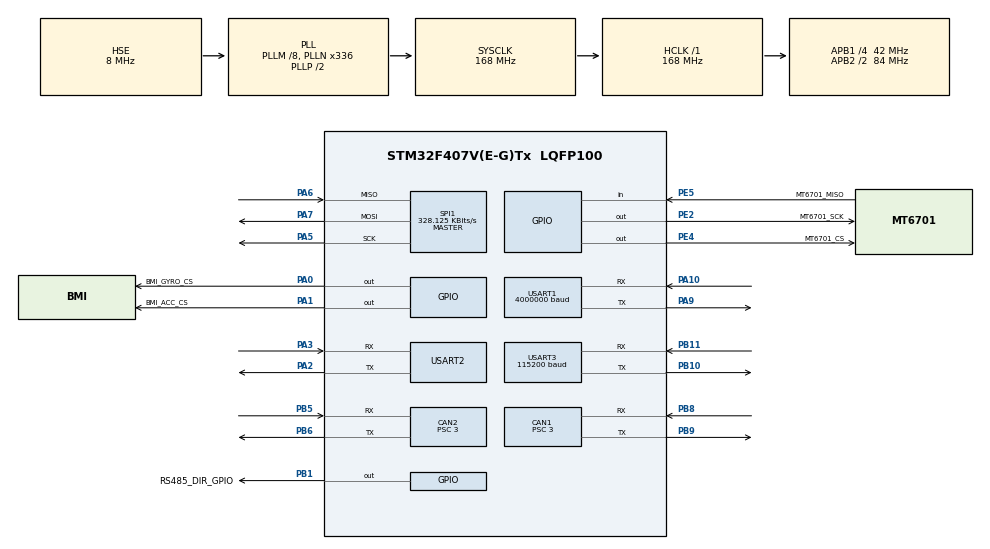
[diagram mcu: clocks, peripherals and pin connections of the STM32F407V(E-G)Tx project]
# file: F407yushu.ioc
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CAN1.ABOM=ENABLE
CAN1.AWUM=DISABLE
CAN1.BS1=CAN_BS1_8TQ
CAN1.BS2=CAN_BS2_5TQ
CAN1.CalculateBaudRate=1000000
CAN1.CalculateTimeQuantum=71.42857142857143
CAN1.Mode=CAN_MODE_NORMAL
CAN1.NART=ENABLE
CAN1.Prescaler=3
CAN1.RFLM=DISABLE
CAN1.SJW=CAN_SJW_1TQ
CAN1.TTCM=DISABLE
CAN1.TXFP=DISABLE
CAN2.ABOM=ENABLE
CAN2.AWUM=DISABLE
CAN2.BS1=CAN_BS1_8TQ
CAN2.BS2=CAN_BS2_5TQ
CAN2.CalculateBaudRate=1000000
CAN2.CalculateTimeQuantum=71.42857142857143
CAN2.Mode=CAN_MODE_NORMAL
CAN2.NART=ENABLE
CAN2.Prescaler=3
CAN2.RFLM=DISABLE
CAN2.SJW=CAN_SJW_1TQ
CAN2.TTCM=DISABLE
CAN2.TXFP=DISABLE
Mcu.Family=STM32F4
Mcu.Name=STM32F407V(E-G)Tx
Mcu.Package=LQFP100
NVIC.CAN1_RX0_IRQn=true\:0\:0\:false\:false\:true\:true\:true\:true
NVIC.CAN1_RX1_IRQn=true\:0\:0\:false\:false\:true\:true\:true\:true
NVIC.CAN1_SCE_IRQn=true\:0\:0\:false\:false\:true\:true\:true\:true
NVIC.CAN1_TX_IRQn=true\:0\:0\:false\:false\:true\:true\:true\:true
NVIC.CAN2_RX0_IRQn=true\:0\:0\:false\:false\:true\:true\:true\:true
NVIC.CAN2_RX1_IRQn=true\:0\:0\:false\:false\:true\:true\:true\:true
NVIC.CAN2_SCE_IRQn=true\:0\:0\:false\:false\:true\:true\:true\:true
NVIC.CAN2_TX_IRQn=true\:0\:0\:false\:false\:true\:true\:true\:true
NVIC.PriorityGroup=NVIC_PRIORITYGROUP_4
PA0-WKUP.GPIO_Label=BMI_GYRO_CS
PA0-WKUP.GPIO_PuPd=GPIO_NOPULL
PA0-WKUP.GPIO_Speed=GPIO_SPEED_FREQ_VERY_HIGH
PA0-WKUP.PinState=GPIO_PIN_SET
PA0-WKUP.Signal=GPIO_Output
PA1.GPIO_Label=BMI_ACC_CS
PA1.GPIO_PuPd=GPIO_NOPULL
PA1.GPIO_Speed=GPIO_SPEED_FREQ_VERY_HIGH
PA1.PinState=GPIO_PIN_SET
PA1.Signal=GPIO_Output
PA10.Mode=Asynchronous
PA10.Signal=USART1_RX
PA13.Mode=Serial_Wire
PA13.Signal=SYS_JTMS-SWDIO
PA14.Mode=Serial_Wire
PA14.Signal=SYS_JTCK-SWCLK
PA2.Mode=Asynchronous
PA2.Signal=USART2_TX
PA3.Mode=Asynchronous
PA3.Signal=USART2_RX
PA5.Mode=Full_Duplex_Master
PA5.Signal=SPI1_SCK
PA6.Mode=Full_Duplex_Master
PA6.Signal=SPI1_MISO
PA7.Mode=Full_Duplex_Master
PA7.Signal=SPI1_MOSI
PA9.Mode=Asynchronous
PA9.Signal=USART1_TX
PB1.GPIO_Label=RS485_DIR_GPIO
PB1.Signal=GPIO_Output
PB10.Mode=Asynchronous
PB10.Signal=USART3_TX
PB11.Mode=Asynchronous
PB11.Signal=USART3_RX
PB5.Mode=CAN_Activate
PB5.Signal=CAN2_RX
PB6.Mode=CAN_Activate
PB6.Signal=CAN2_TX
PB8.Mode=CAN_Activate
PB8.Signal=CAN1_RX
PB9.Mode=CAN_Activate
PB9.Signal=CAN1_TX
PE2.GPIO_Label=MT6701_SCK
PE2.GPIO_PuPd=GPIO_NOPULL
PE2.GPIO_Speed=GPIO_SPEED_FREQ_VERY_HIGH
PE2.PinState=GPIO_PIN_SET
PE2.Signal=GPIO_Output
PE4.GPIO_Label=MT6701_CS
PE4.GPIO_PuPd=GPIO_NOPULL
PE4.GPIO_Speed=GPIO_SPEED_FREQ_VERY_HIGH
PE4.PinState=GPIO_PIN_SET
PE4.Signal=GPIO_Output
PE5.GPIO_Label=MT6701_MISO
PE5.GPIO_PuPd=GPIO_NOPULL
PE5.Signal=GPIO_Input
PH0-OSC_IN.Mode=HSE-External-Oscillator
PH0-OSC_IN.Signal=RCC_OSC_IN
PH1-OSC_OUT.Mode=HSE-External-Oscillator
PH1-OSC_OUT.Signal=RCC_OSC_OUT
ProjectManager.HeapSize=0x200
ProjectManager.StackSize=0x2000
ProjectManager.TargetToolchain=MDK-ARM V5.32
RCC.48MHZClocksFreq_Value=84000000
RCC.AHBFreq_Value=168000000
RCC.APB1CLKDivider=RCC_HCLK_DIV4
RCC.APB1Freq_Value=42000000
RCC.APB1TimFreq_Value=84000000
RCC.APB2CLKDivider=RCC_HCLK_DIV2
RCC.APB2Freq_Value=84000000
RCC.APB2TimFreq_Value=168000000
RCC.CortexFreq_Value=168000000
RCC.HCLKFreq_Value=168000000
RCC.HSE_VALUE=8000000
RCC.HSI_VALUE=16000000
RCC.LSE_VALUE=32768
RCC.PLLM=8
RCC.PLLN=336
RCC.PLLSourceVirtual=RCC_PLLSOURCE_HSE
RCC.SYSCLKFreq_VALUE=168000000
RCC.SYSCLKSource=RCC_SYSCLKSOURCE_PLLCLK
RCC.VCOOutputFreq_Value=336000000
SPI1.BaudRatePrescaler=SPI_BAUDRATEPRESCALER_256
SPI1.CLKPhase=SPI_PHASE_1EDGE
SPI1.CLKPolarity=SPI_POLARITY_LOW
SPI1.CalculateBaudRate=328.125 KBits/s
SPI1.Direction=SPI_DIRECTION_2LINES
SPI1.Mode=SPI_MODE_MASTER
SPI1.VirtualType=VM_MASTER
USART1.BaudRate=4000000
USART1.OverSampling=UART_OVERSAMPLING_8
USART1.VirtualMode=VM_ASYNC
USART2.VirtualMode=VM_ASYNC
USART3.BaudRate=115200
USART3.OverSampling=UART_OVERSAMPLING_16
USART3.VirtualMode=VM_ASYNC
board=custom

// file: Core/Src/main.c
/* USER CODE BEGIN Header */
/**
  ******************************************************************************
  * @file           : main.c
  * @brief          : Main program body
  ******************************************************************************
  * @attention
  *
  * Copyright (c) 2026 STMicroelectronics.
  * All rights reserved.
  *
  * This software is licensed under terms that can be found in the LICENSE file
  * in the root directory of this software component.
  * If no LICENSE file comes with this software, it is provided AS-IS.
  *
  ******************************************************************************
  */
/* USER CODE END Header */
#include "main.h"

/* USER CODE BEGIN Includes */
#include "app.h"

/* USER CODE END Includes */

CAN_HandleTypeDef hcan1;
CAN_HandleTypeDef hcan2;

SPI_HandleTypeDef hspi1;

UART_HandleTypeDef huart1;
UART_HandleTypeDef huart2;
UART_HandleTypeDef huart3;

void SystemClock_Config(void);
static void MX_GPIO_Init(void);
static void MX_USART1_UART_Init(void);
static void MX_USART2_UART_Init(void);
static void MX_USART3_UART_Init(void);
static void MX_CAN1_Init(void);
static void MX_CAN2_Init(void);
static void MX_SPI1_Init(void);

int main(void)
{

  /* MCU Configuration--------------------------------------------------------*/

  /* Reset of all peripherals, Initializes the Flash interface and the Systick. */
  HAL_Init();

  /* Configure the system clock */
  SystemClock_Config();

  /* Initialize all configured peripherals */
  MX_GPIO_Init();
  MX_USART1_UART_Init();
  MX_USART2_UART_Init();
  MX_USART3_UART_Init();
  MX_CAN1_Init();
  MX_CAN2_Init();
  MX_SPI1_Init();
  /* USER CODE BEGIN 2 */
  App_Init();
  /* USER CODE END 2 */

  /* Infinite loop */
  while (1)
  {

    /* USER CODE BEGIN 3 */
    App_RunOnce();
  }
  /* USER CODE END 3 */
}

void SystemClock_Config(void)
{
  RCC_OscInitTypeDef RCC_OscInitStruct = {0};
  RCC_ClkInitTypeDef RCC_ClkInitStruct = {0};

  /** Configure the main internal regulator output voltage
  */
  __HAL_RCC_PWR_CLK_ENABLE();
  __HAL_PWR_VOLTAGESCALING_CONFIG(PWR_REGULATOR_VOLTAGE_SCALE1);

  /** Initializes the RCC Oscillators according to the specified parameters
  * in the RCC_OscInitTypeDef structure.
  */
  RCC_OscInitStruct.OscillatorType = RCC_OSCILLATORTYPE_HSE;
  RCC_OscInitStruct.HSEState = RCC_HSE_ON;
  RCC_OscInitStruct.PLL.PLLState = RCC_PLL_ON;
  RCC_OscInitStruct.PLL.PLLSource = RCC_PLLSOURCE_HSE;
  RCC_OscInitStruct.PLL.PLLM = 8;
  RCC_OscInitStruct.PLL.PLLN = 336;
  RCC_OscInitStruct.PLL.PLLP = RCC_PLLP_DIV2;
  RCC_OscInitStruct.PLL.PLLQ = 4;
  if (HAL_RCC_OscConfig(&RCC_OscInitStruct) != HAL_OK)
  {
    Error_Handler();
  }

  /** Initializes the CPU, AHB and APB buses clocks
  */
  RCC_ClkInitStruct.ClockType = RCC_CLOCKTYPE_HCLK|RCC_CLOCKTYPE_SYSCLK
                              |RCC_CLOCKTYPE_PCLK1|RCC_CLOCKTYPE_PCLK2;
  RCC_ClkInitStruct.SYSCLKSource = RCC_SYSCLKSOURCE_PLLCLK;
  RCC_ClkInitStruct.AHBCLKDivider = RCC_SYSCLK_DIV1;
  RCC_ClkInitStruct.APB1CLKDivider = RCC_HCLK_DIV4;
  RCC_ClkInitStruct.APB2CLKDivider = RCC_HCLK_DIV2;

  if (HAL_RCC_ClockConfig(&RCC_ClkInitStruct, FLASH_LATENCY_5) != HAL_OK)
  {
    Error_Handler();
  }
}

static void MX_CAN1_Init(void)
{

  hcan1.Instance = CAN1;
  hcan1.Init.Prescaler = 3;
  hcan1.Init.Mode = CAN_MODE_NORMAL;
  hcan1.Init.SyncJumpWidth = CAN_SJW_1TQ;
  hcan1.Init.TimeSeg1 = CAN_BS1_8TQ;
  hcan1.Init.TimeSeg2 = CAN_BS2_5TQ;
  hcan1.Init.TimeTriggeredMode = DISABLE;
  hcan1.Init.AutoBusOff = ENABLE;
  hcan1.Init.AutoWakeUp = DISABLE;
  hcan1.Init.AutoRetransmission = ENABLE;
  hcan1.Init.ReceiveFifoLocked = DISABLE;
  hcan1.Init.TransmitFifoPriority = DISABLE;
  if (HAL_CAN_Init(&hcan1) != HAL_OK)
  {
    Error_Handler();
  }

}

static void MX_CAN2_Init(void)
{

  hcan2.Instance = CAN2;
  hcan2.Init.Prescaler = 3;
  hcan2.Init.Mode = CAN_MODE_NORMAL;
  hcan2.Init.SyncJumpWidth = CAN_SJW_1TQ;
  hcan2.Init.TimeSeg1 = CAN_BS1_8TQ;
  hcan2.Init.TimeSeg2 = CAN_BS2_5TQ;
  hcan2.Init.TimeTriggeredMode = DISABLE;
  hcan2.Init.AutoBusOff = ENABLE;
  hcan2.Init.AutoWakeUp = DISABLE;
  hcan2.Init.AutoRetransmission = ENABLE;
  hcan2.Init.ReceiveFifoLocked = DISABLE;
  hcan2.Init.TransmitFifoPriority = DISABLE;
  if (HAL_CAN_Init(&hcan2) != HAL_OK)
  {
    Error_Handler();
  }

}

static void MX_SPI1_Init(void)
{

  /* SPI1 parameter configuration*/
  hspi1.Instance = SPI1;
  hspi1.Init.Mode = SPI_MODE_MASTER;
  hspi1.Init.Direction = SPI_DIRECTION_2LINES;
  hspi1.Init.DataSize = SPI_DATASIZE_8BIT;
  hspi1.Init.CLKPolarity = SPI_POLARITY_LOW;
  hspi1.Init.CLKPhase = SPI_PHASE_1EDGE;
  hspi1.Init.NSS = SPI_NSS_SOFT;
  hspi1.Init.BaudRatePrescaler = SPI_BAUDRATEPRESCALER_256;
  hspi1.Init.FirstBit = SPI_FIRSTBIT_MSB;
  hspi1.Init.TIMode = SPI_TIMODE_DISABLE;
  hspi1.Init.CRCCalculation = SPI_CRCCALCULATION_DISABLE;
  hspi1.Init.CRCPolynomial = 10;
  if (HAL_SPI_Init(&hspi1) != HAL_OK)
  {
    Error_Handler();
  }

}

static void MX_USART1_UART_Init(void)
{

  huart1.Instance = USART1;
  huart1.Init.BaudRate = 4000000;
  huart1.Init.WordLength = UART_WORDLENGTH_8B;
  huart1.Init.StopBits = UART_STOPBITS_1;
  huart1.Init.Parity = UART_PARITY_NONE;
  huart1.Init.Mode = UART_MODE_TX_RX;
  huart1.Init.HwFlowCtl = UART_HWCONTROL_NONE;
  huart1.Init.OverSampling = UART_OVERSAMPLING_8;
  if (HAL_UART_Init(&huart1) != HAL_OK)
  {
    Error_Handler();
  }

}

static void MX_USART2_UART_Init(void)
{

  huart2.Instance = USART2;
  huart2.Init.BaudRate = 115200;
  huart2.Init.WordLength = UART_WORDLENGTH_8B;
  huart2.Init.StopBits = UART_STOPBITS_1;
  huart2.Init.Parity = UART_PARITY_NONE;
  huart2.Init.Mode = UART_MODE_TX_RX;
  huart2.Init.HwFlowCtl = UART_HWCONTROL_NONE;
  huart2.Init.OverSampling = UART_OVERSAMPLING_16;
  if (HAL_UART_Init(&huart2) != HAL_OK)
  {
    Error_Handler();
  }

}

static void MX_USART3_UART_Init(void)
{

  huart3.Instance = USART3;
  huart3.Init.BaudRate = 115200;
  huart3.Init.WordLength = UART_WORDLENGTH_8B;
  huart3.Init.StopBits = UART_STOPBITS_1;
  huart3.Init.Parity = UART_PARITY_NONE;
  huart3.Init.Mode = UART_MODE_TX_RX;
  huart3.Init.HwFlowCtl = UART_HWCONTROL_NONE;
  huart3.Init.OverSampling = UART_OVERSAMPLING_16;
  if (HAL_UART_Init(&huart3) != HAL_OK)
  {
    Error_Handler();
  }

}

static void MX_GPIO_Init(void)
{
  GPIO_InitTypeDef GPIO_InitStruct = {0};

  /* GPIO Ports Clock Enable */
  __HAL_RCC_GPIOE_CLK_ENABLE();
  __HAL_RCC_GPIOH_CLK_ENABLE();
  __HAL_RCC_GPIOA_CLK_ENABLE();
  __HAL_RCC_GPIOB_CLK_ENABLE();

  /*Configure GPIO pin Output Level */
  HAL_GPIO_WritePin(GPIOE, MT6701_SCK_Pin|MT6701_CS_Pin, GPIO_PIN_SET);

  /*Configure GPIO pin Output Level */
  HAL_GPIO_WritePin(GPIOA, BMI_GYRO_CS_Pin|BMI_ACC_CS_Pin, GPIO_PIN_SET);

  /*Configure GPIO pin Output Level */
  HAL_GPIO_WritePin(RS485_DIR_GPIO_GPIO_Port, RS485_DIR_GPIO_Pin, GPIO_PIN_RESET);

  /*Configure GPIO pins : MT6701_SCK_Pin MT6701_CS_Pin */
  GPIO_InitStruct.Pin = MT6701_SCK_Pin|MT6701_CS_Pin;
  GPIO_InitStruct.Mode = GPIO_MODE_OUTPUT_PP;
  GPIO_InitStruct.Pull = GPIO_NOPULL;
  GPIO_InitStruct.Speed = GPIO_SPEED_FREQ_VERY_HIGH;
  HAL_GPIO_Init(GPIOE, &GPIO_InitStruct);

  /*Configure GPIO pin : MT6701_MISO_Pin */
  GPIO_InitStruct.Pin = MT6701_MISO_Pin;
  GPIO_InitStruct.Mode = GPIO_MODE_INPUT;
  GPIO_InitStruct.Pull = GPIO_NOPULL;
  HAL_GPIO_Init(MT6701_MISO_GPIO_Port, &GPIO_InitStruct);

  /*Configure GPIO pins : BMI_GYRO_CS_Pin BMI_ACC_CS_Pin */
  GPIO_InitStruct.Pin = BMI_GYRO_CS_Pin|BMI_ACC_CS_Pin;
  GPIO_InitStruct.Mode = GPIO_MODE_OUTPUT_PP;
  GPIO_InitStruct.Pull = GPIO_NOPULL;
  GPIO_InitStruct.Speed = GPIO_SPEED_FREQ_VERY_HIGH;
  HAL_GPIO_Init(GPIOA, &GPIO_InitStruct);

  /*Configure GPIO pin : RS485_DIR_GPIO_Pin */
  GPIO_InitStruct.Pin = RS485_DIR_GPIO_Pin;
  GPIO_InitStruct.Mode = GPIO_MODE_OUTPUT_PP;
  GPIO_InitStruct.Pull = GPIO_NOPULL;
  GPIO_InitStruct.Speed = GPIO_SPEED_FREQ_LOW;
  HAL_GPIO_Init(RS485_DIR_GPIO_GPIO_Port, &GPIO_InitStruct);

}

void Error_Handler(void)
{
  /* USER CODE BEGIN Error_Handler_Debug */
  while (1)
  {
    App_ErrorHandlerStep();
  }
  /* USER CODE END Error_Handler_Debug */
}
